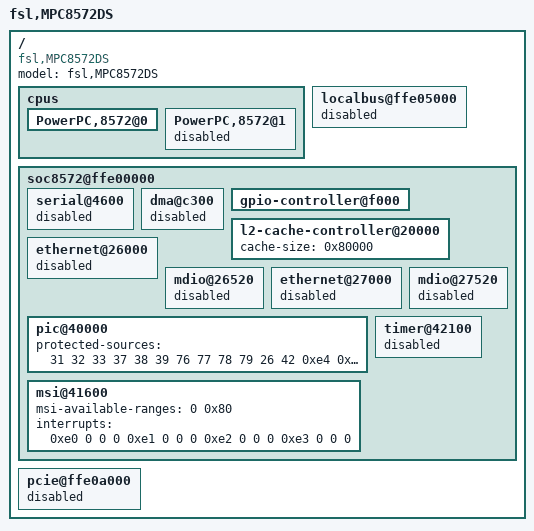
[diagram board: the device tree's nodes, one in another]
/include/ "mpc8572ds.dts"
/ {
	model = "fsl,MPC8572DS";
	compatible = "fsl,MPC8572DS", "fsl,MPC8572DS-CAMP";
	cpus {
		PowerPC,8572@0 {
		};
		PowerPC,8572@1 {
			status = "disabled";
		};
	};
	localbus@ffe05000 {
		status = "disabled";
	};
	soc8572@ffe00000 {
		serial@4600 {
			status = "disabled";
		};
		dma@c300 {
			status = "disabled";
		};
		gpio-controller@f000 {
		};
		l2-cache-controller@20000 {
			cache-size = <0x80000>;	 
		};
		ethernet@26000 {
			status = "disabled";
		};
		mdio@26520 {
			status = "disabled";
		};
		ethernet@27000 {
			status = "disabled";
		};
		mdio@27520 {
			status = "disabled";
		};
		pic@40000 {
			protected-sources = <
			31 32 33 37 38 39        
			76 77 78 79 26 42	 
			0xe4 0xe5 0xe6 0xe7	 
			>;
		};
		msi@41600 {
			msi-available-ranges = <0 0x80>;
			interrupts = <
				0xe0 0 0 0
				0xe1 0 0 0
				0xe2 0 0 0
				0xe3 0 0 0>;
		};
		timer@42100 {
			status = "disabled";
		};
	};
	pcie@ffe0a000 {
		status = "disabled";
	};
};
